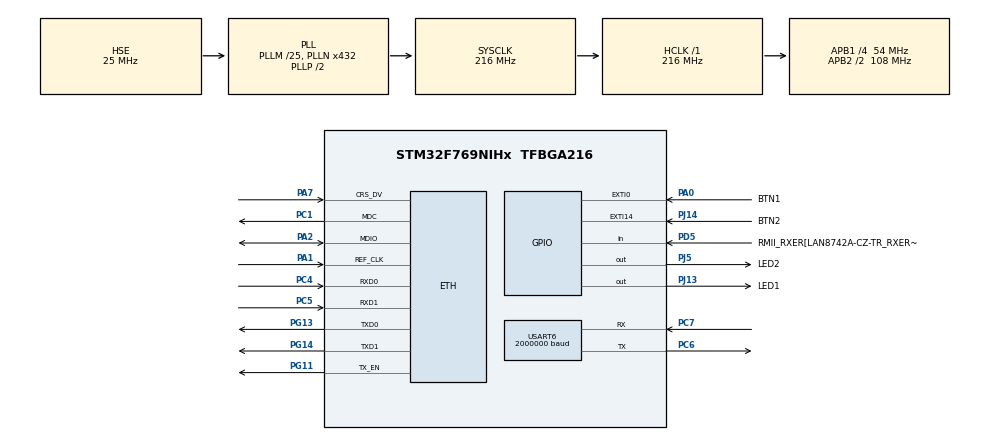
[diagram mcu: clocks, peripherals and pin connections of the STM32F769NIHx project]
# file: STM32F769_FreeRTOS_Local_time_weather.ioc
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ETH.ETH_RX_DESC_CNT=8
ETH.ETH_TX_DESC_CNT=8
ETH.MediaInterface=HAL_ETH_RMII_MODE
ETH.RxMode=ETH_RXINTERRUPT_MODE
FREERTOS.Tasks01=defaultTask,0,384,StartDefaultTask,Default,NULL,Dynamic,NULL,NULL
FREERTOS.configCHECK_FOR_STACK_OVERFLOW=2
FREERTOS.configENABLE_FPU=1
FREERTOS.configGENERATE_RUN_TIME_STATS=1
FREERTOS.configTOTAL_HEAP_SIZE=131072
FREERTOS.configUSE_APPLICATION_TASK_TAG=1
FREERTOS.configUSE_COUNTING_SEMAPHORES=1
FREERTOS.configUSE_IDLE_HOOK=1
FREERTOS.configUSE_MALLOC_FAILED_HOOK=1
FREERTOS.configUSE_RECURSIVE_MUTEXES=1
FREERTOS.configUSE_STATS_FORMATTING_FUNCTIONS=1
LWIP.BSP.number=1
LWIP.GATEWAY_ADDRESS=010.000.000.001
LWIP.IP_ADDRESS=010.000.000.004
LWIP.LWIP_DBG_MIN_LEVEL=LWIP_DBG_LEVEL_ALL
LWIP.LWIP_DHCP=1
LWIP.LWIP_DNS=1
LWIP.LWIP_NETIF_STATUS_CALLBACK=1
LWIP.NETMASK_ADDRESS=255.255.255.000
LWIP.Version=v2.1.2_Cube
LWIP0.BSP.STBoard=false
LWIP0.BSP.api=BSP_COMPONENT_DRIVER
LWIP0.BSP.component=LAN8742
LWIP0.BSP.instance=LAN8742
LWIP0.BSP.name=Driver_PHY
LWIP0.BSP.semaphore=S_LAN8742
LWIP0.BSP.solution=LAN8742
Mcu.Family=STM32F7
Mcu.Name=STM32F769NIHx
Mcu.Package=TFBGA216
NVIC.ETH_IRQn=true\:5\:0\:false\:false\:true\:true\:true\:true\:true
NVIC.EXTI0_IRQn=true\:5\:0\:false\:false\:true\:true\:true\:true\:true
NVIC.EXTI15_10_IRQn=true\:5\:0\:false\:false\:true\:true\:true\:true\:true
NVIC.PriorityGroup=NVIC_PRIORITYGROUP_4
NVIC.TIM6_DAC_IRQn=true\:15\:0\:false\:false\:true\:false\:false\:true\:true
NVIC.TimeBase=TIM6_DAC_IRQn
NVIC.TimeBaseIP=TIM6
PA0/WKUP.GPIO_Label=BTN1
PA0/WKUP.Signal=GPXTI0
PA1.Mode=RMII
PA1.Signal=ETH_REF_CLK
PA13.Mode=Serial_Wire
PA13.Signal=SYS_JTMS-SWDIO
PA14.Mode=Serial_Wire
PA14.Signal=SYS_JTCK-SWCLK
PA2.Mode=RMII
PA2.Signal=ETH_MDIO
PA7.Mode=RMII
PA7.Signal=ETH_CRS_DV
PC1.Mode=RMII
PC1.Signal=ETH_MDC
PC14/OSC32_IN.Mode=LSE-External-Oscillator
PC14/OSC32_IN.Signal=RCC_OSC32_IN
PC15/OSC32_OUT.Mode=LSE-External-Oscillator
PC15/OSC32_OUT.Signal=RCC_OSC32_OUT
PC4.Mode=RMII
PC4.Signal=ETH_RXD0
PC5.Mode=RMII
PC5.Signal=ETH_RXD1
PC6.Mode=Asynchronous
PC6.Signal=USART6_TX
PC7.Mode=Asynchronous
PC7.Signal=USART6_RX
PD5.GPIO_Label=RMII_RXER[LAN8742A-CZ-TR_RXERR]
PD5.Signal=GPIO_Input
PG11.Mode=RMII
PG11.Signal=ETH_TX_EN
PG13.Mode=RMII
PG13.Signal=ETH_TXD0
PG14.Mode=RMII
PG14.Signal=ETH_TXD1
PH0/OSC_IN.Mode=HSE-External-Oscillator
PH0/OSC_IN.Signal=RCC_OSC_IN
PH1/OSC_OUT.Mode=HSE-External-Oscillator
PH1/OSC_OUT.Signal=RCC_OSC_OUT
PJ13.GPIO_Label=LED1
PJ13.Signal=GPIO_Output
PJ14.GPIO_Label=BTN2
PJ14.Signal=GPXTI14
PJ5.GPIO_Label=LED2
PJ5.Signal=GPIO_Output
ProjectManager.HeapSize=0x200
ProjectManager.StackSize=0x400
ProjectManager.TargetToolchain=STM32CubeIDE
RCC.AHBFreq_Value=216000000
RCC.APB1CLKDivider=RCC_HCLK_DIV4
RCC.APB1Freq_Value=54000000
RCC.APB1TimFreq_Value=108000000
RCC.APB2CLKDivider=RCC_HCLK_DIV2
RCC.APB2Freq_Value=108000000
RCC.APB2TimFreq_Value=216000000
RCC.CortexFreq_Value=216000000
RCC.HCLKFreq_Value=216000000
RCC.HSE_VALUE=25000000
RCC.HSI_VALUE=16000000
RCC.PLL48CLockSelection=RCC_CLK48SOURCE_PLLSAIP
RCC.PLLM=25
RCC.PLLN=432
RCC.PLLSAIP=RCC_PLLSAIP_DIV4
RCC.PLLSourceVirtual=RCC_PLLSOURCE_HSE
RCC.PWR_Regulator_Voltage_Scale=PWR_REGULATOR_VOLTAGE_SCALE1
RCC.RTCClockSelection=RCC_RTCCLKSOURCE_LSE
RCC.SYSCLKFreq_VALUE=216000000
RCC.SYSCLKSource=RCC_SYSCLKSOURCE_PLLCLK
RCC.USBFreq_Value=48000000
RCC.VCOOutputFreq_Value=432000000
RTC.Format=RTC_FORMAT_BCD
TIM5.Period=0xffffffff
TIM5.Prescaler=108-1
USART6.BaudRate=2000000
USART6.VirtualMode-Asynchronous=VM_ASYNC
VP_FREERTOS_VS_CMSIS_V1.Mode=CMSIS_V1
VP_LWIP_VS_Enabled.Mode=Enabled
VP_RTC_VS_RTC_Activate.Mode=RTC_Enabled
VP_RTC_VS_RTC_Calendar.Mode=RTC_Calendar
VP_SYS_VS_tim6.Mode=TIM6
VP_TIM5_VS_ClockSourceINT.Mode=Internal
board=custom

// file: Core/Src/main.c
/* USER CODE BEGIN Header */
/**
  ******************************************************************************
  * @file           : main.c
  * @brief          : Main program body
  ******************************************************************************
  * @attention
  *
  * Copyright (c) 2026 STMicroelectronics.
  * All rights reserved.
  *
  * This software is licensed under terms that can be found in the LICENSE file
  * in the root directory of this software component.
  * If no LICENSE file comes with this software, it is provided AS-IS.
  *
  ******************************************************************************
  */
/* USER CODE END Header */
#include "main.h"
#include "cmsis_os.h"
#include "lwip.h"

/* USER CODE BEGIN Includes */
#include "tasks_init.h"
#include "system_stats_task.h"
#include "ntp_client_task.h"
/* USER CODE END Includes */

RTC_HandleTypeDef hrtc;

TIM_HandleTypeDef htim5;

UART_HandleTypeDef huart6;

osThreadId defaultTaskHandle;

void SystemClock_Config(void);
static void MX_GPIO_Init(void);
static void MX_TIM5_Init(void);
static void MX_USART6_UART_Init(void);
static void MX_RTC_Init(void);
void StartDefaultTask(void const * argument);

/* USER CODE BEGIN 0 */
/**
 * @brief External interrupt callback
 */
void HAL_GPIO_EXTI_Callback(uint16_t GPIO_Pin){
	if(GPIO_Pin == BTN2_Pin) {
		print_system_stats_FromISR();
	}
}
/* USER CODE END 0 */

int main(void)
{

  /* MCU Configuration--------------------------------------------------------*/

  /* Reset of all peripherals, Initializes the Flash interface and the Systick. */
  HAL_Init();

  /* Configure the system clock */
  SystemClock_Config();

  /* Initialize all configured peripherals */
  MX_GPIO_Init();
  MX_TIM5_Init();
  MX_USART6_UART_Init();
  MX_RTC_Init();

  /* Create the thread(s) */
  /* definition and creation of defaultTask */
  osThreadDef(defaultTask, StartDefaultTask, osPriorityNormal, 0, 384);
  defaultTaskHandle = osThreadCreate(osThread(defaultTask), NULL);

  /* USER CODE BEGIN RTOS_THREADS */

  tasks_create_all();
  /* USER CODE END RTOS_THREADS */

  /* Start scheduler */
  osKernelStart();

  /* We should never get here as control is now taken by the scheduler */

  /* Infinite loop */
  while (1)
  {

  }
}

void SystemClock_Config(void)
{
  RCC_OscInitTypeDef RCC_OscInitStruct = {0};
  RCC_ClkInitTypeDef RCC_ClkInitStruct = {0};

  /** Configure LSE Drive Capability
  */
  HAL_PWR_EnableBkUpAccess();
  __HAL_RCC_LSEDRIVE_CONFIG(RCC_LSEDRIVE_LOW);

  /** Configure the main internal regulator output voltage
  */
  __HAL_RCC_PWR_CLK_ENABLE();
  __HAL_PWR_VOLTAGESCALING_CONFIG(PWR_REGULATOR_VOLTAGE_SCALE1);

  /** Initializes the RCC Oscillators according to the specified parameters
  * in the RCC_OscInitTypeDef structure.
  */
  RCC_OscInitStruct.OscillatorType = RCC_OSCILLATORTYPE_HSE|RCC_OSCILLATORTYPE_LSE;
  RCC_OscInitStruct.HSEState = RCC_HSE_ON;
  RCC_OscInitStruct.LSEState = RCC_LSE_ON;
  RCC_OscInitStruct.PLL.PLLState = RCC_PLL_ON;
  RCC_OscInitStruct.PLL.PLLSource = RCC_PLLSOURCE_HSE;
  RCC_OscInitStruct.PLL.PLLM = 25;
  RCC_OscInitStruct.PLL.PLLN = 432;
  RCC_OscInitStruct.PLL.PLLP = RCC_PLLP_DIV2;
  RCC_OscInitStruct.PLL.PLLQ = 2;
  RCC_OscInitStruct.PLL.PLLR = 2;
  if (HAL_RCC_OscConfig(&RCC_OscInitStruct) != HAL_OK)
  {
    Error_Handler();
  }

  /** Activate the Over-Drive mode
  */
  if (HAL_PWREx_EnableOverDrive() != HAL_OK)
  {
    Error_Handler();
  }

  /** Initializes the CPU, AHB and APB buses clocks
  */
  RCC_ClkInitStruct.ClockType = RCC_CLOCKTYPE_HCLK|RCC_CLOCKTYPE_SYSCLK
                              |RCC_CLOCKTYPE_PCLK1|RCC_CLOCKTYPE_PCLK2;
  RCC_ClkInitStruct.SYSCLKSource = RCC_SYSCLKSOURCE_PLLCLK;
  RCC_ClkInitStruct.AHBCLKDivider = RCC_SYSCLK_DIV1;
  RCC_ClkInitStruct.APB1CLKDivider = RCC_HCLK_DIV4;
  RCC_ClkInitStruct.APB2CLKDivider = RCC_HCLK_DIV2;

  if (HAL_RCC_ClockConfig(&RCC_ClkInitStruct, FLASH_LATENCY_7) != HAL_OK)
  {
    Error_Handler();
  }
}

static void MX_RTC_Init(void)
{

  RTC_TimeTypeDef sTime = {0};
  RTC_DateTypeDef sDate = {0};

  /** Initialize RTC Only
  */
  hrtc.Instance = RTC;
  hrtc.Init.HourFormat = RTC_HOURFORMAT_24;
  hrtc.Init.AsynchPrediv = 127;
  hrtc.Init.SynchPrediv = 255;
  hrtc.Init.OutPut = RTC_OUTPUT_DISABLE;
  hrtc.Init.OutPutPolarity = RTC_OUTPUT_POLARITY_HIGH;
  hrtc.Init.OutPutType = RTC_OUTPUT_TYPE_OPENDRAIN;
  if (HAL_RTC_Init(&hrtc) != HAL_OK)
  {
    Error_Handler();
  }

  /** Initialize RTC and set the Time and Date
  */
  sTime.Hours = 0x0;
  sTime.Minutes = 0x0;
  sTime.Seconds = 0x0;
  sTime.DayLightSaving = RTC_DAYLIGHTSAVING_NONE;
  sTime.StoreOperation = RTC_STOREOPERATION_RESET;
  if (HAL_RTC_SetTime(&hrtc, &sTime, RTC_FORMAT_BCD) != HAL_OK)
  {
    Error_Handler();
  }
  sDate.WeekDay = RTC_WEEKDAY_MONDAY;
  sDate.Month = RTC_MONTH_JANUARY;
  sDate.Date = 0x1;
  sDate.Year = 0x0;

  if (HAL_RTC_SetDate(&hrtc, &sDate, RTC_FORMAT_BCD) != HAL_OK)
  {
    Error_Handler();
  }

}

static void MX_TIM5_Init(void)
{

  TIM_ClockConfigTypeDef sClockSourceConfig = {0};
  TIM_MasterConfigTypeDef sMasterConfig = {0};

  htim5.Instance = TIM5;
  htim5.Init.Prescaler = 108-1;
  htim5.Init.CounterMode = TIM_COUNTERMODE_UP;
  htim5.Init.Period = 0xffffffff;
  htim5.Init.ClockDivision = TIM_CLOCKDIVISION_DIV1;
  htim5.Init.AutoReloadPreload = TIM_AUTORELOAD_PRELOAD_DISABLE;
  if (HAL_TIM_Base_Init(&htim5) != HAL_OK)
  {
    Error_Handler();
  }
  sClockSourceConfig.ClockSource = TIM_CLOCKSOURCE_INTERNAL;
  if (HAL_TIM_ConfigClockSource(&htim5, &sClockSourceConfig) != HAL_OK)
  {
    Error_Handler();
  }
  sMasterConfig.MasterOutputTrigger = TIM_TRGO_RESET;
  sMasterConfig.MasterSlaveMode = TIM_MASTERSLAVEMODE_DISABLE;
  if (HAL_TIMEx_MasterConfigSynchronization(&htim5, &sMasterConfig) != HAL_OK)
  {
    Error_Handler();
  }

}

static void MX_USART6_UART_Init(void)
{

  huart6.Instance = USART6;
  huart6.Init.BaudRate = 2000000;
  huart6.Init.WordLength = UART_WORDLENGTH_8B;
  huart6.Init.StopBits = UART_STOPBITS_1;
  huart6.Init.Parity = UART_PARITY_NONE;
  huart6.Init.Mode = UART_MODE_TX_RX;
  huart6.Init.HwFlowCtl = UART_HWCONTROL_NONE;
  huart6.Init.OverSampling = UART_OVERSAMPLING_16;
  huart6.Init.OneBitSampling = UART_ONE_BIT_SAMPLE_DISABLE;
  huart6.AdvancedInit.AdvFeatureInit = UART_ADVFEATURE_NO_INIT;
  if (HAL_UART_Init(&huart6) != HAL_OK)
  {
    Error_Handler();
  }

}

static void MX_GPIO_Init(void)
{
  GPIO_InitTypeDef GPIO_InitStruct = {0};

  /* GPIO Ports Clock Enable */
  __HAL_RCC_GPIOG_CLK_ENABLE();
  __HAL_RCC_GPIOA_CLK_ENABLE();
  __HAL_RCC_GPIOJ_CLK_ENABLE();
  __HAL_RCC_GPIOD_CLK_ENABLE();
  __HAL_RCC_GPIOC_CLK_ENABLE();
  __HAL_RCC_GPIOH_CLK_ENABLE();

  /*Configure GPIO pin Output Level */
  HAL_GPIO_WritePin(GPIOJ, LED1_Pin|LED2_Pin, GPIO_PIN_RESET);

  /*Configure GPIO pins : LED1_Pin LED2_Pin */
  GPIO_InitStruct.Pin = LED1_Pin|LED2_Pin;
  GPIO_InitStruct.Mode = GPIO_MODE_OUTPUT_PP;
  GPIO_InitStruct.Pull = GPIO_NOPULL;
  GPIO_InitStruct.Speed = GPIO_SPEED_FREQ_LOW;
  HAL_GPIO_Init(GPIOJ, &GPIO_InitStruct);

  /*Configure GPIO pin : BTN2_Pin */
  GPIO_InitStruct.Pin = BTN2_Pin;
  GPIO_InitStruct.Mode = GPIO_MODE_IT_RISING;
  GPIO_InitStruct.Pull = GPIO_NOPULL;
  HAL_GPIO_Init(BTN2_GPIO_Port, &GPIO_InitStruct);

  /*Configure GPIO pin : RMII_RXER_Pin */
  GPIO_InitStruct.Pin = RMII_RXER_Pin;
  GPIO_InitStruct.Mode = GPIO_MODE_INPUT;
  GPIO_InitStruct.Pull = GPIO_NOPULL;
  HAL_GPIO_Init(RMII_RXER_GPIO_Port, &GPIO_InitStruct);

  /*Configure GPIO pin : BTN1_Pin */
  GPIO_InitStruct.Pin = BTN1_Pin;
  GPIO_InitStruct.Mode = GPIO_MODE_IT_RISING;
  GPIO_InitStruct.Pull = GPIO_NOPULL;
  HAL_GPIO_Init(BTN1_GPIO_Port, &GPIO_InitStruct);

  /* EXTI interrupt init*/
  HAL_NVIC_SetPriority(EXTI0_IRQn, 5, 0);
  HAL_NVIC_EnableIRQ(EXTI0_IRQn);

  HAL_NVIC_SetPriority(EXTI15_10_IRQn, 5, 0);
  HAL_NVIC_EnableIRQ(EXTI15_10_IRQn);

}

void StartDefaultTask(void const * argument)
{
  /* init code for LWIP */
  MX_LWIP_Init();
  for(;;)
  {
    osDelay(1);
  }
}

void HAL_TIM_PeriodElapsedCallback(TIM_HandleTypeDef *htim)
{
  if (htim->Instance == TIM6)
  {
    HAL_IncTick();
  }
}

void Error_Handler(void)
{
  __disable_irq();
  while (1)
  {
  }
}

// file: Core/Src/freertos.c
/* USER CODE BEGIN Header */
/**
  ******************************************************************************
  * File Name          : freertos.c
  * Description        : Code for freertos applications
  ******************************************************************************
  * @attention
  *
  * Copyright (c) 2026 STMicroelectronics.
  * All rights reserved.
  *
  * This software is licensed under terms that can be found in the LICENSE file
  * in the root directory of this software component.
  * If no LICENSE file comes with this software, it is provided AS-IS.
  *
  ******************************************************************************
  */
/* USER CODE END Header */

#include "FreeRTOS.h"
#include "task.h"
#include "main.h"

/* GetIdleTaskMemory prototype (linked to static allocation support) */
void vApplicationGetIdleTaskMemory( StaticTask_t **ppxIdleTaskTCBBuffer, StackType_t **ppxIdleTaskStackBuffer, uint32_t *pulIdleTaskStackSize );

/* Hook prototypes */
void configureTimerForRunTimeStats(void);
unsigned long getRunTimeCounterValue(void);
void vApplicationIdleHook(void);
void vApplicationStackOverflowHook(xTaskHandle xTask, signed char *pcTaskName);
void vApplicationMallocFailedHook(void);

/* USER CODE BEGIN 1 */
/* Functions needed when configGENERATE_RUN_TIME_STATS is on */
__weak void configureTimerForRunTimeStats(void)
{

}

__weak unsigned long getRunTimeCounterValue(void)
{
return 0;
}
/* USER CODE END 1 */

/* USER CODE BEGIN 2 */
__weak void vApplicationIdleHook( void )
{
   /* vApplicationIdleHook() will only be called if configUSE_IDLE_HOOK is set
   to 1 in FreeRTOSConfig.h. It will be called on each iteration of the idle
   task. It is essential that code added to this hook function never attempts
   to block in any way (for example, call xQueueReceive() with a block time
   specified, or call vTaskDelay()). If the application makes use of the
   vTaskDelete() API function (as this demo application does) then it is also
   important that vApplicationIdleHook() is permitted to return to its calling
   function, because it is the responsibility of the idle task to clean up
   memory allocated by the kernel to any task that has since been deleted. */
}
/* USER CODE END 2 */

/* USER CODE BEGIN 4 */
__weak void vApplicationStackOverflowHook(xTaskHandle xTask, signed char *pcTaskName)
{
   /* Run time stack overflow checking is performed if
   configCHECK_FOR_STACK_OVERFLOW is defined to 1 or 2. This hook function is
   called if a stack overflow is detected. */
}
/* USER CODE END 4 */

/* USER CODE BEGIN 5 */
__weak void vApplicationMallocFailedHook(void)
{
   /* vApplicationMallocFailedHook() will only be called if
   configUSE_MALLOC_FAILED_HOOK is set to 1 in FreeRTOSConfig.h. It is a hook
   function that will get called if a call to pvPortMalloc() fails.
   pvPortMalloc() is called internally by the kernel whenever a task, queue,
   timer or semaphore is created. It is also called by various parts of the
   demo application. If heap_1.c or heap_2.c are used, then the size of the
   heap available to pvPortMalloc() is defined by configTOTAL_HEAP_SIZE in
   FreeRTOSConfig.h, and the xPortGetFreeHeapSize() API function can be used
   to query the size of free heap space that remains (although it does not
   provide information on how the remaining heap might be fragmented). */
}
/* USER CODE END 5 */

/* USER CODE BEGIN GET_IDLE_TASK_MEMORY */
static StaticTask_t xIdleTaskTCBBuffer;
static StackType_t xIdleStack[configMINIMAL_STACK_SIZE];

void vApplicationGetIdleTaskMemory( StaticTask_t **ppxIdleTaskTCBBuffer, StackType_t **ppxIdleTaskStackBuffer, uint32_t *pulIdleTaskStackSize )
{
  *ppxIdleTaskTCBBuffer = &xIdleTaskTCBBuffer;
  *ppxIdleTaskStackBuffer = &xIdleStack[0];
  *pulIdleTaskStackSize = configMINIMAL_STACK_SIZE;
  /* place for user code */
}
/* USER CODE END GET_IDLE_TASK_MEMORY */
